# Espressif register map
File version: 1.0
CPU: Xtensa LX6 1, little endian, no MPU, FPU, 3 interrupt priority bits
Registers are 32-bit, access not given, reset 0x0 unless marked. A register's access mark holds for its fields unless they carry their own. Offsets are from the block's base; [hi:lo] are bit positions; {n}, {i} and the like mark numbered series.

## APB_CTRL
Base 0x3FF66000
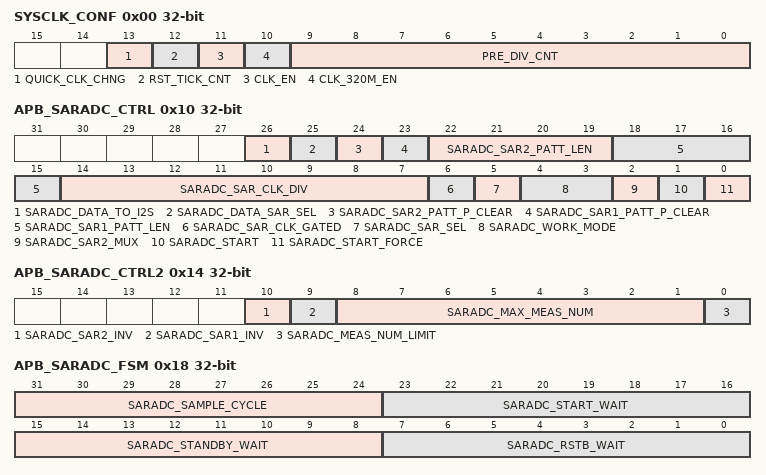
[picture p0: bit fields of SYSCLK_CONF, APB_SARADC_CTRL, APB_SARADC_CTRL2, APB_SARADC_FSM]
0x00 SYSCLK_CONF — APB_CTRL_SYSCLK_CONF
  [13] QUICK_CLK_CHNG, [12] RST_TICK_CNT, [11] CLK_EN, [10] CLK_320M_EN, [9:0] PRE_DIV_CNT
0x04 XTAL_TICK_CONF — APB_CTRL_XTAL_TICK_CONF
  [7:0] XTAL_TICK_NUM
0x08 PLL_TICK_CONF — APB_CTRL_PLL_TICK_CONF
  [7:0] PLL_TICK_NUM
0x0C CK8M_TICK_CONF — APB_CTRL_CK8M_TICK_CONF
  [7:0] CK8M_TICK_NUM
0x10 APB_SARADC_CTRL — APB_CTRL_APB_SARADC_CTRL
  [26] SARADC_DATA_TO_I2S, [25] SARADC_DATA_SAR_SEL, [24] SARADC_SAR2_PATT_P_CLEAR, [23] SARADC_SAR1_PATT_P_CLEAR, [22:19] SARADC_SAR2_PATT_LEN, [18:15] SARADC_SAR1_PATT_LEN, [14:7] SARADC_SAR_CLK_DIV, [6] SARADC_SAR_CLK_GATED, [5] SARADC_SAR_SEL, [4:3] SARADC_WORK_MODE, [2] SARADC_SAR2_MUX, [1] SARADC_START, [0] SARADC_START_FORCE
0x14 APB_SARADC_CTRL2 — APB_CTRL_APB_SARADC_CTRL2
  [10] SARADC_SAR2_INV, [9] SARADC_SAR1_INV, [8:1] SARADC_MAX_MEAS_NUM, [0] SARADC_MEAS_NUM_LIMIT
0x18 APB_SARADC_FSM — APB_CTRL_APB_SARADC_FSM
  [31:24] SARADC_SAMPLE_CYCLE, [23:16] SARADC_START_WAIT, [15:8] SARADC_STANDBY_WAIT, [7:0] SARADC_RSTB_WAIT
{0x18+4i} APB_SARADC_SAR1_PATT_TAB{i} (i=1..4) — APB_CTRL_APB_SARADC_SAR1_PATT_TAB{i}
  [31:0] SARADC_SAR1_PATT_TAB{i}
{0x28+4i} APB_SARADC_SAR2_PATT_TAB{i} (i=1..4) — APB_CTRL_APB_SARADC_SAR2_PATT_TAB{i}
  [31:0] SARADC_SAR2_PATT_TAB{i}
0x3C APLL_TICK_CONF — APB_CTRL_APLL_TICK_CONF
  [7:0] APLL_TICK_NUM
0x7C DATE — APB_CTRL_DATE

## SYSCON
Base 0x3FF66000
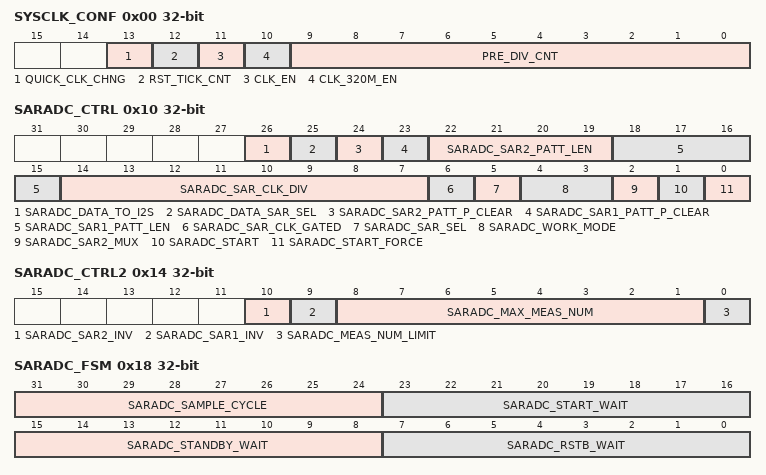
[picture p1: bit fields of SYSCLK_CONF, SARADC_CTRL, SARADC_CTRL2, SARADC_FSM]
0x00 SYSCLK_CONF — SYSCON_SYSCLK_CONF
  [13] QUICK_CLK_CHNG, [12] RST_TICK_CNT, [11] CLK_EN, [10] CLK_320M_EN, [9:0] PRE_DIV_CNT
0x04 XTAL_TICK_CONF — SYSCON_XTAL_TICK_CONF
  [7:0] XTAL_TICK_NUM
0x08 PLL_TICK_CONF — SYSCON_PLL_TICK_CONF
  [7:0] PLL_TICK_NUM
0x0C CK8M_TICK_CONF — SYSCON_CK8M_TICK_CONF
  [7:0] CK8M_TICK_NUM
0x10 SARADC_CTRL — SYSCON_SARADC_CTRL
  [26] SARADC_DATA_TO_I2S, [25] SARADC_DATA_SAR_SEL, [24] SARADC_SAR2_PATT_P_CLEAR, [23] SARADC_SAR1_PATT_P_CLEAR, [22:19] SARADC_SAR2_PATT_LEN, [18:15] SARADC_SAR1_PATT_LEN, [14:7] SARADC_SAR_CLK_DIV, [6] SARADC_SAR_CLK_GATED, [5] SARADC_SAR_SEL, [4:3] SARADC_WORK_MODE, [2] SARADC_SAR2_MUX, [1] SARADC_START, [0] SARADC_START_FORCE
0x14 SARADC_CTRL2 — SYSCON_SARADC_CTRL2
  [10] SARADC_SAR2_INV, [9] SARADC_SAR1_INV, [8:1] SARADC_MAX_MEAS_NUM, [0] SARADC_MEAS_NUM_LIMIT
0x18 SARADC_FSM — SYSCON_SARADC_FSM
  [31:24] SARADC_SAMPLE_CYCLE, [23:16] SARADC_START_WAIT, [15:8] SARADC_STANDBY_WAIT, [7:0] SARADC_RSTB_WAIT
{0x18+4i} SARADC_SAR1_PATT_TAB{i} (i=1..4) — SYSCON_SARADC_SAR1_PATT_TAB{i}
{0x28+4i} SARADC_SAR2_PATT_TAB{i} (i=1..4) — SYSCON_SARADC_SAR2_PATT_TAB{i}
0x3C APLL_TICK_CONF — SYSCON_APLL_TICK_CONF
  [7:0] APLL_TICK_NUM
0x7C DATE — SYSCON_DATE

## RTC_I2C
Base 0x3FF48C00
0x00 SCL_LOW_PERIOD — RTC_I2C_SCL_LOW_PERIOD
  [18:0] SCL_LOW_PERIOD
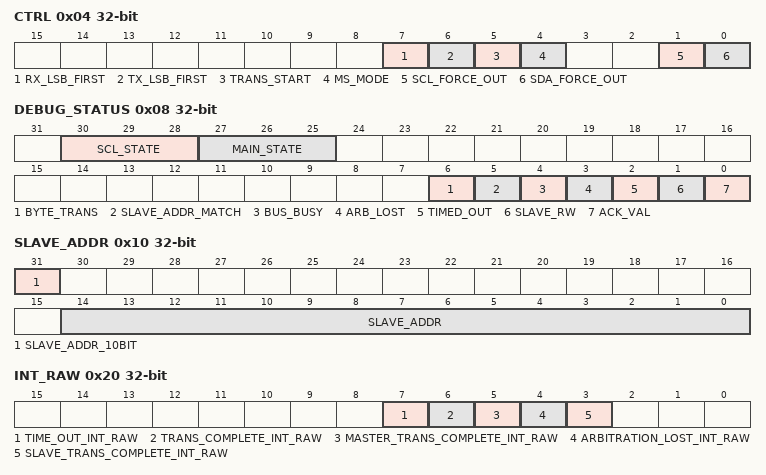
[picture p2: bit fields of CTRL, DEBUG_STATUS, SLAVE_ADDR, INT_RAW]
0x04 CTRL — RTC_I2C_CTRL
  [7] RX_LSB_FIRST, [6] TX_LSB_FIRST, [5] TRANS_START, [4] MS_MODE, [1] SCL_FORCE_OUT, [0] SDA_FORCE_OUT
0x08 DEBUG_STATUS — RTC_I2C_DEBUG_STATUS
  [30:28] SCL_STATE, [27:25] MAIN_STATE, [6] BYTE_TRANS, [5] SLAVE_ADDR_MATCH, [4] BUS_BUSY, [3] ARB_LOST, [2] TIMED_OUT, [1] SLAVE_RW, [0] ACK_VAL
0x0C TIMEOUT — RTC_I2C_TIMEOUT
  [19:0] TIMEOUT
0x10 SLAVE_ADDR — RTC_I2C_SLAVE_ADDR
  [31] SLAVE_ADDR_10BIT, [14:0] SLAVE_ADDR
0x20 INT_RAW — RTC_I2C_INT_RAW
  [7] TIME_OUT_INT_RAW, [6] TRANS_COMPLETE_INT_RAW, [5] MASTER_TRANS_COMPLETE_INT_RAW, [4] ARBITRATION_LOST_INT_RAW, [3] SLAVE_TRANS_COMPLETE_INT_RAW
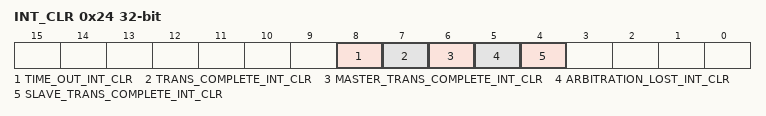
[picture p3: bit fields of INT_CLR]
0x24 INT_CLR — RTC_I2C_INT_CLR
  [8] TIME_OUT_INT_CLR, [7] TRANS_COMPLETE_INT_CLR, [6] MASTER_TRANS_COMPLETE_INT_CLR, [5] ARBITRATION_LOST_INT_CLR, [4] SLAVE_TRANS_COMPLETE_INT_CLR
0x30 SDA_DUTY — RTC_I2C_SDA_DUTY
  [19:0] SDA_DUTY
0x38 SCL_HIGH_PERIOD — RTC_I2C_SCL_HIGH_PERIOD
  [19:0] SCL_HIGH_PERIOD
0x40 SCL_START_PERIOD — RTC_I2C_SCL_START_PERIOD
  [19:0] SCL_START_PERIOD
0x44 SCL_STOP_PERIOD — RTC_I2C_SCL_STOP_PERIOD
  [19:0] SCL_STOP_PERIOD
